VERSION ""

NS_ :

BS_:

BU_:

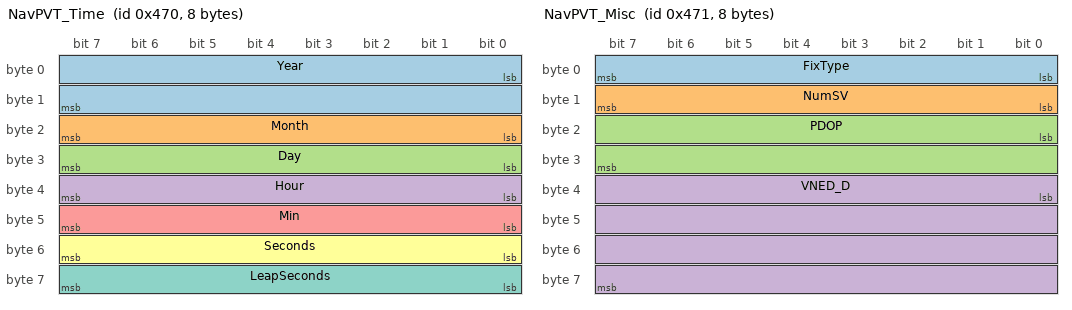
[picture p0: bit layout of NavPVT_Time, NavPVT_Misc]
BO_ 1136 NavPVT_Time: 8 Vector__XXX
	SG_ Year : 0|16@1+ (0,0) [0|0] "" Vector__XXX
	SG_ Month : 16|8@1+ (0,0) [0|0] "" Vector__XXX
	SG_ Day : 24|8@1+ (0,0) [0|0] "" Vector__XXX
	SG_ Hour : 32|8@1+ (0,0) [0|0] "" Vector__XXX
	SG_ Min : 40|8@1+ (0,0) [0|0] "" Vector__XXX
	SG_ Seconds : 48|8@1+ (0,0) [0|0] "" Vector__XXX
	SG_ LeapSeconds : 56|8@1+ (0,0) [0|0] "" Vector__XXX

BO_ 1137 NavPVT_Misc: 8 Vector__XXX
	SG_ FixType : 0|8@1+ (0,0) [0|0] "" Vector__XXX
	SG_ NumSV : 8|8@1+ (0,0) [0|0] "" Vector__XXX
	SG_ PDOP : 16|16@1+ (0,0) [0|0] "" Vector__XXX
	SG_ VNED_D : 32|32@1+ (0,0) [0|0] "" Vector__XXX

BO_ 1138 NavPVT_LatLon: 8 Vector__XXX
	SG_ longitude : 0|32@1+ (0,0) [0|0] "" Vector__XXX
	SG_ latitude : 32|32@1+ (0,0) [0|0] "" Vector__XXX

BO_ 1139 NavPVT_Height: 8 Vector__XXX
	SG_ height : 0|32@1+ (0,0) [0|0] "" Vector__XXX
	SG_ heightMSL : 32|32@1+ (0,0) [0|0] "" Vector__XXX

BO_ 1140 NavPVT_VNED: 8 Vector__XXX
	SG_ VNED_N : 0|32@1+ (0,0) [0|0] "" Vector__XXX
	SG_ VNED_E : 32|32@1+ (0,0) [0|0] "" Vector__XXX

BO_ 1141 NavCOV_PartA: 8 Vector__XXX
	SG_ posCovNN : 0|32@1+ (0,0) [0|0] "" Vector__XXX
	SG_ posCovNE : 32|32@1+ (0,0) [0|0] "" Vector__XXX

BO_ 1142 NavCOV_PartB: 8 Vector__XXX
	SG_ posCovND : 0|32@1+ (0,0) [0|0] "" Vector__XXX
	SG_ velCovNN : 32|32@1+ (0,0) [0|0] "" Vector__XXX

BO_ 1143 NavCOV_PartC: 8 Vector__XXX
	SG_ velCovNE : 0|32@1+ (0,0) [0|0] "" Vector__XXX
	SG_ velCovND : 32|32@1+ (0,0) [0|0] "" Vector__XXX

BO_ 1144 NavSOL_PartA: 8 Vector__XXX
	SG_ ecefX : 0|32@1+ (0,0) [0|0] "" Vector__XXX
	SG_ ecefY : 32|32@1+ (0,0) [0|0] "" Vector__XXX

BO_ 1145 NavSOL_PartB: 8 Vector__XXX
	SG_ ecefZ : 0|32@1+ (0,0) [0|0] "" Vector__XXX
	SG_ ecefVX : 32|32@1+ (0,0) [0|0] "" Vector__XXX

BO_ 1152 NavSOL_PartC: 8 Vector__XXX
	SG_ ecefVY : 0|32@1+ (0,0) [0|0] "" Vector__XXX
	SG_ ecefVZ : 32|32@1+ (0,0) [0|0] "" Vector__XXX

BO_ 1153 GNSS_HeartBeat: 8 Vector__XXX
	SG_ Heartbeat : 0|64@1+ (0,0) [0|0] "" Vector__XXX

CM_ BO_ 1136 "UBX_NAV_PVT Time and Date";
CM_ BO_ 1137 "UBX_NAV_PVT Fix Type, numSV, VNED D, PDOP";
CM_ BO_ 1138 "UBX_NAV_PVT Latitude and Longitude";
CM_ BO_ 1139 "UBX_NAV_PVT height, msl height";
CM_ BO_ 1140 "UBX_NAV_PVT VNED N, VNED E";
CM_ BO_ 1141 "UBX_NAV_COV posCovNN, posCovNE";
CM_ BO_ 1142 "UBX_NAV_COV posCovND, velCovNN";
CM_ BO_ 1143 "UBX_NAV_COV velCovNE, velCovND";
CM_ BO_ 1144 "UBX_NAV_SOL ecefX, ecefY";
CM_ BO_ 1145 "UBX_NAV_SOL ecefZ, ecefVX";
CM_ BO_ 1152 "UBX_NAV_SOL ecefVY, ecefVZ";
BA_DEF_ BO_  "VFrameFormat" ENUM  "StandardCAN","ExtendedCAN","reserved","J1939PG";
BA_DEF_  "DatabaseVersion" STRING ;
BA_DEF_  "BusType" STRING ;
BA_DEF_  "ProtocolType" STRING ;
BA_DEF_DEF_  "VFrameFormat" "J1939PG";
BA_DEF_DEF_  "BusType" "";
BA_DEF_DEF_  "ProtocolType" "";
BA_ "ProtocolType" "J1939";
BA_ "BusType" "CAN";
BA_ "DatabaseVersion" "1.0.0";
